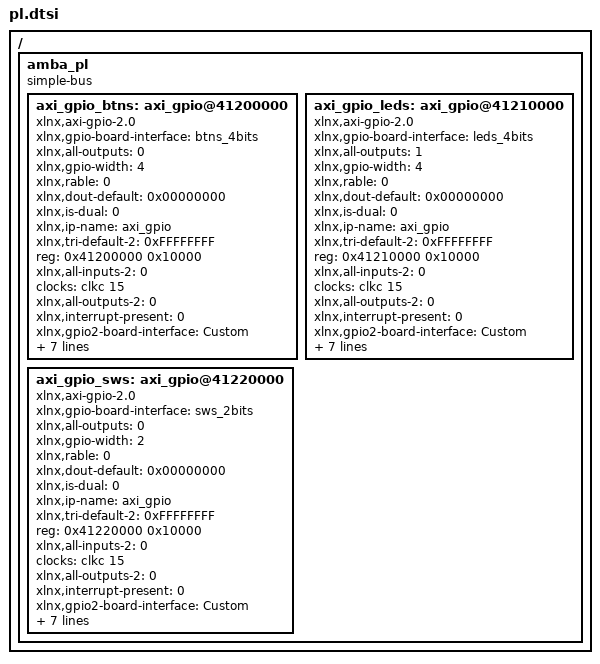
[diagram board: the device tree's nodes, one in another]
/ {
	amba_pl: amba_pl {
		ranges;
		compatible = "simple-bus";
		#address-cells = <1>;
		#size-cells = <1>;
		axi_gpio_btns: axi_gpio@41200000 {
			xlnx,gpio-board-interface = "btns_4bits";
			compatible = "xlnx,axi-gpio-2.0" , "xlnx,xps-gpio-1.00.a";
			xlnx,all-outputs = <0>;
			xlnx,gpio-width = <4>;
			xlnx,rable = <0>;
			xlnx,dout-default = <0x00000000>;
			xlnx,is-dual = <0>;
			xlnx,ip-name = "axi_gpio";
			xlnx,tri-default-2 = <0xFFFFFFFF>;
			reg = <0x41200000 0x10000>;
			xlnx,all-inputs-2 = <0>;
			clocks = <&clkc 15>;
			xlnx,all-outputs-2 = <0>;
			xlnx,interrupt-present = <0>;
			xlnx,gpio2-board-interface = "Custom";
			xlnx,edk-iptype = "PERIPHERAL";
			xlnx,dout-default-2 = <0x00000000>;
			xlnx,gpio2-width = <32>;
			status = "okay";
			clock-names = "s_axi_aclk";
			xlnx,use-board-flow;
			xlnx,tri-default = <0xFFFFFFFF>;
			xlnx,name = "axi_gpio_btns";
			xlnx,all-inputs = <1>;
		};
		axi_gpio_leds: axi_gpio@41210000 {
			xlnx,gpio-board-interface = "leds_4bits";
			compatible = "xlnx,axi-gpio-2.0" , "xlnx,xps-gpio-1.00.a";
			xlnx,all-outputs = <1>;
			xlnx,gpio-width = <4>;
			xlnx,rable = <0>;
			xlnx,dout-default = <0x00000000>;
			xlnx,is-dual = <0>;
			xlnx,ip-name = "axi_gpio";
			xlnx,tri-default-2 = <0xFFFFFFFF>;
			reg = <0x41210000 0x10000>;
			xlnx,all-inputs-2 = <0>;
			clocks = <&clkc 15>;
			xlnx,all-outputs-2 = <0>;
			xlnx,interrupt-present = <0>;
			xlnx,gpio2-board-interface = "Custom";
			xlnx,edk-iptype = "PERIPHERAL";
			xlnx,dout-default-2 = <0x00000000>;
			xlnx,gpio2-width = <32>;
			status = "okay";
			clock-names = "s_axi_aclk";
			xlnx,use-board-flow;
			xlnx,tri-default = <0xFFFFFFFF>;
			xlnx,name = "axi_gpio_leds";
			xlnx,all-inputs = <0>;
		};
		axi_gpio_sws: axi_gpio@41220000 {
			xlnx,gpio-board-interface = "sws_2bits";
			compatible = "xlnx,axi-gpio-2.0" , "xlnx,xps-gpio-1.00.a";
			xlnx,all-outputs = <0>;
			xlnx,gpio-width = <2>;
			xlnx,rable = <0>;
			xlnx,dout-default = <0x00000000>;
			xlnx,is-dual = <0>;
			xlnx,ip-name = "axi_gpio";
			xlnx,tri-default-2 = <0xFFFFFFFF>;
			reg = <0x41220000 0x10000>;
			xlnx,all-inputs-2 = <0>;
			clocks = <&clkc 15>;
			xlnx,all-outputs-2 = <0>;
			xlnx,interrupt-present = <0>;
			xlnx,gpio2-board-interface = "Custom";
			xlnx,edk-iptype = "PERIPHERAL";
			xlnx,dout-default-2 = <0x00000000>;
			xlnx,gpio2-width = <32>;
			status = "okay";
			clock-names = "s_axi_aclk";
			xlnx,use-board-flow;
			xlnx,tri-default = <0xFFFFFFFF>;
			xlnx,name = "axi_gpio_sws";
			xlnx,all-inputs = <1>;
		};
	};
};
